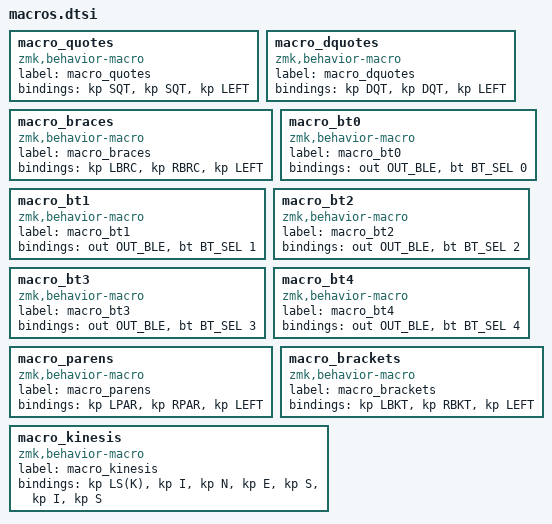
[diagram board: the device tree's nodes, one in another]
macro_quotes: macro_quotes{
compatible = "zmk,behavior-macro";
label = "macro_quotes";
#binding-cells = <0>;
bindings = <&kp SQT>, <&kp SQT>, <&kp LEFT>;
};
macro_dquotes: macro_dquotes{
compatible = "zmk,behavior-macro";
label = "macro_dquotes";
#binding-cells = <0>;
bindings = <&kp DQT>, <&kp DQT>, <&kp LEFT>;
};
macro_braces: macro_braces{
compatible = "zmk,behavior-macro";
label = "macro_braces";
#binding-cells = <0>;
bindings = <&kp LBRC>, <&kp RBRC>, <&kp LEFT>;
};
macro_bt0: macro_bt0{
compatible = "zmk,behavior-macro";
label = "macro_bt0";
#binding-cells = <0>; // Must be 0
bindings = <&out OUT_BLE>, <&bt BT_SEL 0>;
};
macro_bt1: macro_bt1{
compatible = "zmk,behavior-macro";
label = "macro_bt1";
#binding-cells = <0>; // Must be 0
bindings = <&out OUT_BLE>, <&bt BT_SEL 1>;
};
macro_bt2: macro_bt2{
compatible = "zmk,behavior-macro";
label = "macro_bt2";
#binding-cells = <0>; // Must be 0
bindings = <&out OUT_BLE>, <&bt BT_SEL 2>;
};
macro_bt3: macro_bt3{
compatible = "zmk,behavior-macro";
label = "macro_bt3";
#binding-cells = <0>; // Must be 0
bindings = <&out OUT_BLE>, <&bt BT_SEL 3>;
};
macro_bt4: macro_bt4{
compatible = "zmk,behavior-macro";
label = "macro_bt4";
#binding-cells = <0>; // Must be 0
bindings = <&out OUT_BLE>, <&bt BT_SEL 4>;
};
macro_parens: macro_parens{
compatible = "zmk,behavior-macro";
label = "macro_parens";
#binding-cells = <0>;
bindings = <&kp LPAR>, <&kp RPAR>, <&kp LEFT>;
};
macro_brackets: macro_brackets{
compatible = "zmk,behavior-macro";
label = "macro_brackets";
#binding-cells = <0>;
bindings = <&kp LBKT>, <&kp RBKT>, <&kp LEFT>;
};
macro_kinesis: macro_kinesis{
compatible = "zmk,behavior-macro";
label = "macro_kinesis";
#binding-cells = <0>;
bindings = <&kp LS(K)>, <&kp I>, <&kp N>, <&kp E>, <&kp S>, <&kp I>, <&kp S>;
};
